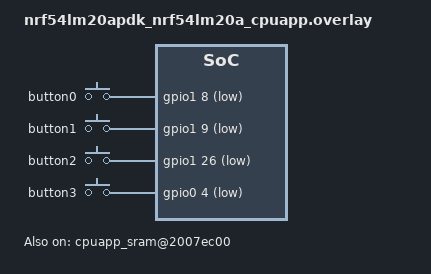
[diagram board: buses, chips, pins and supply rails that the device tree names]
/ {
	/* seems that for now P1.26 doesn't work, let's switch with button2. */
	/delete-node/ buttons;
	buttons {
		compatible = "gpio-keys";

		button0: button_0 {
			gpios = <&gpio1 8 (GPIO_PULL_UP | GPIO_ACTIVE_LOW)>;
		};

		button1: button_1 {
			gpios = <&gpio1 9 (GPIO_PULL_UP | GPIO_ACTIVE_LOW)>;
		};

		button2: button_2 {
			gpios = <&gpio1 26 (GPIO_PULL_UP | GPIO_ACTIVE_LOW)>;
		};

		button3: button_3 {
			gpios = <&gpio0 4 (GPIO_PULL_UP | GPIO_ACTIVE_LOW)>;
		};
	};

	cpuapp_sram@2007ec00 {
		compatible = "zephyr,memory-region", "mmio-sram";
		reg = <0x2007ec00 DT_SIZE_K(4)>;
		zephyr,memory-region = "RetainedMem";
		status = "okay";

		retainedmem0: retainedmem {
			compatible = "zephyr,retained-ram";
			status = "okay";
		};
	};

	aliases {
		retainedmemdevice = &retainedmem0;
	};
};

&cpuapp_sram {
	/* Shrink SRAM size to avoid overlap with retained memory region:
	 * 511 - 4 = 507KB = 0x7ec00
	 */
	reg = <0x20000000 DT_SIZE_K(507)>;
	ranges = <0x0 0x20000000 0x7ec00>;
};
